# SP28038 register map
Vendor: NXP Semiconductors; Series: SP2083X; File version: 1.0
CPU: CM4 r0p1, little endian, no MPU, FPU, VTOR, 4 interrupt priority bits
Registers are 32-bit, read-write, reset 0x0 unless marked. A register's access mark holds for its fields unless they carry their own. Offsets are from the block's base; [hi:lo] are bit positions; {n}, {i} and the like mark numbered series; 'fields as' and 'values as' point back to an identical list.

## AIPS0 — AIPS-Lite Bridge
Base 0x40000000; register names take the prefix AIPS0_
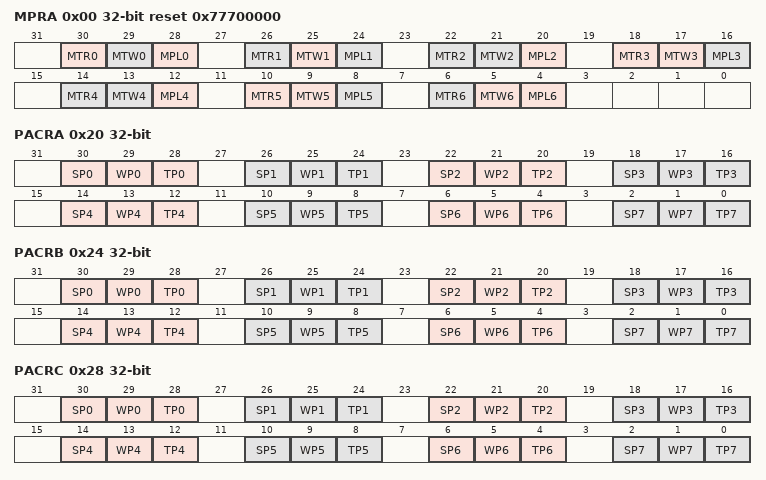
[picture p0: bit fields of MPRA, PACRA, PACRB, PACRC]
0x00 MPRA reset 0x77700000 — Master Privilege Register A
  [30] MTR0 — Master 0 Trusted For Read
    0=This master is not trusted for read accesses; 1=This master is trusted for read accesses
  [29] MTW0 — Master 0 Trusted For Writes
    0=This master is not trusted for write accesses; 1=This master is trusted for write accesses
  [28-4n] MPL{n} (n=0..6) — Master {n} Privilege Level
    0=Accesses from this master are forced to user-mode; 1=Accesses from this master are not forced to user-mode
  [26] MTR1 — Master 1 Trusted for Read
    values as MTR0
  [25] MTW1 — Master 1 Trusted for Writes
    values as MTW0
  [30-4n] MTR{n} (n=2..5) — Master {n} Trusted For Read
    values as MTR0
  [29-4n] MTW{n} (n=2..5) — Master {n} Trusted For Writes
    values as MTW0
  [6] MTR6 — Master 6 Trusted for Read
    values as MTR0
  [5] MTW6 — Master 6 Trusted for Writes
    values as MTW0
0x20 PACRA — Peripheral Access Control Register
  [30-4n] SP{n} (n=0..7) — Supervisor Protect
    0=This peripheral does not require supervisor privilege level for accesses; 1=This peripheral requires supervisor privilege level for accesses
  [29-4n] WP{n} (n=0..7) — Write Protect
    0=This peripheral allows write accesses; 1=This peripheral is write protected
  [28-4n] TP{n} (n=0..7) — Trusted Protect
    0=Accesses from an untrusted master are allowed; 1=Accesses from an untrusted master are not allowed
0x24 PACRB — Peripheral Access Control Register
  fields as PACRA
0x28 PACRC — Peripheral Access Control Register
  fields as PACRA
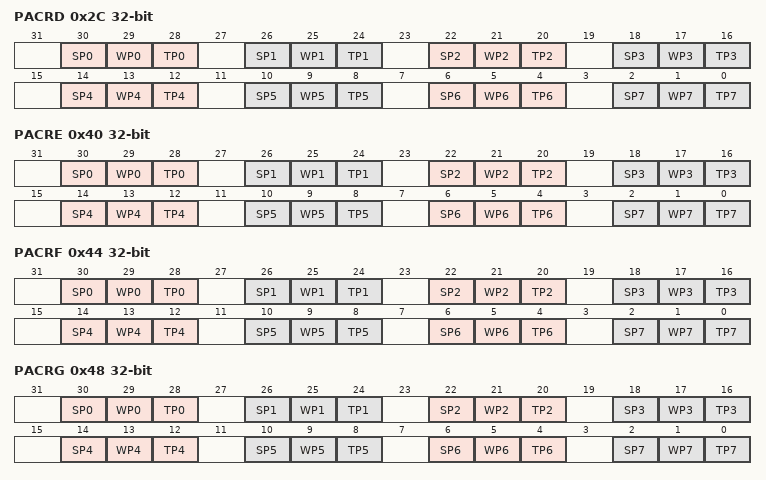
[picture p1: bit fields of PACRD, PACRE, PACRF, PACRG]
0x2C PACRD — Peripheral Access Control Register
  fields as PACRA
0x40 PACRE — Peripheral Access Control Register
  fields as PACRA
0x44 PACRF — Peripheral Access Control Register
  fields as PACRA
0x48 PACRG — Peripheral Access Control Register
  fields as PACRA
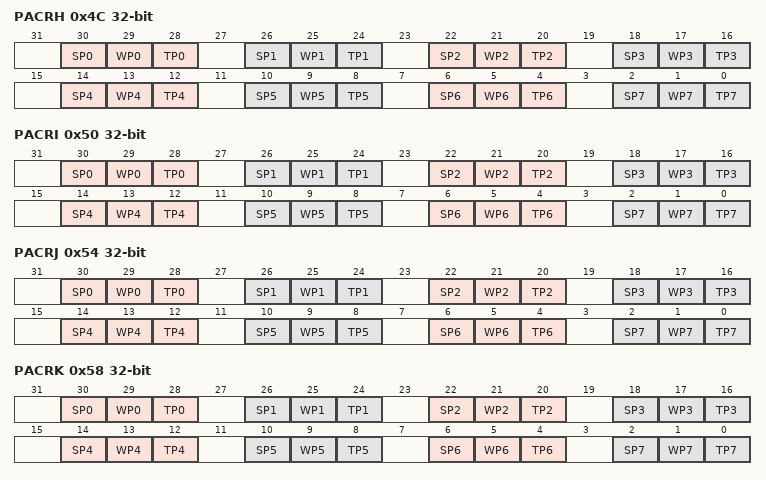
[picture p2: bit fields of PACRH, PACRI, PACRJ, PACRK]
0x4C PACRH — Peripheral Access Control Register
  fields as PACRA
0x50 PACRI — Peripheral Access Control Register
  fields as PACRA
0x54 PACRJ — Peripheral Access Control Register
  fields as PACRA
0x58 PACRK — Peripheral Access Control Register
  fields as PACRA
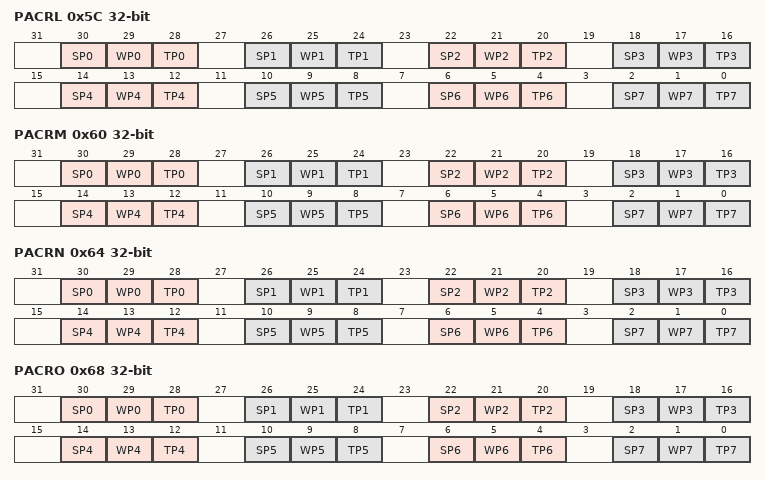
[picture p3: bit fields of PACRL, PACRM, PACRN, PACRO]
0x5C PACRL — Peripheral Access Control Register
  fields as PACRA
0x60 PACRM — Peripheral Access Control Register
  fields as PACRA
0x64 PACRN — Peripheral Access Control Register
  fields as PACRA
0x68 PACRO — Peripheral Access Control Register
  fields as PACRA
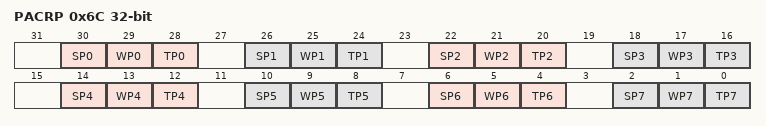
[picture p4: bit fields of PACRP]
0x6C PACRP — Peripheral Access Control Register
  fields as PACRA

## AIPS1 — AIPS-Lite Bridge
Base 0x40080000; register names take the prefix AIPS1_
Registers as AIPS0.

## AXBS — Crossbar switch
Base 0x40004000; register names take the prefix AXBS_
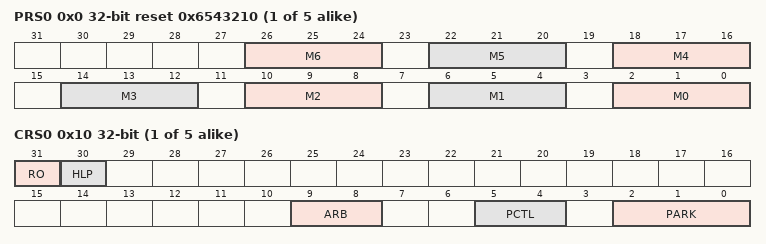
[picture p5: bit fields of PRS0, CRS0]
{0x0+0x100*i} PRS{i} (i=0..4) reset 0x6543210 — Priority Registers Slave
  [all] fields
    0=This master has level 1, or highest, priority when accessing the slave port; {v}=This master has level {v+1} priority when accessing the slave port (v=1..6); 7=This master has level 8, or lowest, priority when accessing the slave port
  [4n+2:4n] M{n} (n=0..6) — Master {n} Priority. Sets the arbitration priority for this port on the associated slave port.
{0x10+0x100*i} CRS{i} (i=0..4) — Control Register
  [31] RO — Read Only
    0=The slave port's registers are writeable; 1=The slave port's registers are read-only and cannot be written. Attempted writes have no effect on the registers and result in a bus error response.
  [30] HLP — Halt Low Priority
    0=The low power mode request has the highest priority for arbitration on this slave port; 1=The low power mode request has the lowest initial priority for arbitration on this slave port
  [9:8] ARB — Arbitration Mode
    0=Fixed priority; 1=Round-robin, or rotating, priority
  [5:4] PCTL — Parking Control
    0=When no master makes a request, the arbiter parks the slave port on the master port defined by the PARK field; 1=When no master makes a request, the arbiter parks the slave port on the last master to be in control of the slave port; 2=When no master makes a request, the slave port is not parked on a master and the arbiter drives all outputs to a constant safe state
  [2:0] PARK
    {v}=Park on master port M{v} (v=0..7)
{0x800+0x100*i} MGPCR{i} (i=0..6) — Master General Purpose Control Register
  [2:0] AULB — Arbitrates On Undefined Length Bursts
    0=No arbitration is allowed during an undefined length burst; 1=Arbitration is allowed at any time during an undefined length burst; 2=Arbitration is allowed after four beats of an undefined length burst; 3=Arbitration is allowed after eight beats of an undefined length burst; 4=Arbitration is allowed after 16 beats of an undefined length burst

## Notices in the file
Copyright 2016-2018 STARPOWER SPDX-License-Identifier: BSD-3-Clause
